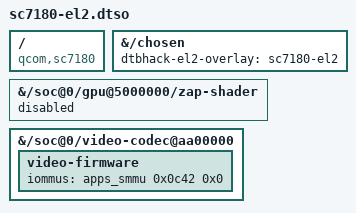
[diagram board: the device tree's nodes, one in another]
// SPDX-License-Identifier: BSD-3-Clause

/*
 * sc7180 specific extensions required to boot in EL2.
 */

/dts-v1/;
/plugin/;

/ {
	/* NixOS tooling wants some reassurance the overlay is compatible with the board. */
	compatible = "qcom,sc7180";
};

&{/chosen} {
	dtbhack-el2-overlay = "sc7180-el2";
};

/* We can't and don't need to use zap shader in EL2. */
&{/soc@0/gpu@5000000/zap-shader} {
	status = "disabled";
};

/* Venus can be used in EL2 using ChromeOS specific mode. */
&{/soc@0/video-codec@aa00000} {
	video-firmware {
		iommus = <&apps_smmu 0x0c42 0x0>;
	};
};
